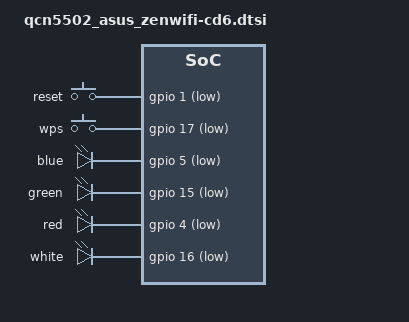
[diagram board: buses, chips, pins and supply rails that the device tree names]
// SPDX-License-Identifier: GPL-2.0-or-later OR MIT

#include "qcn5502_asus.dtsi"

#include <dt-bindings/gpio/gpio.h>
#include <dt-bindings/input/input.h>

/ {
	aliases {
		led-boot = &led_blue;
		led-failsafe = &led_red;
		led-running = &led_blue;
		led-upgrade = &led_red;
	};

	keys {
		compatible = "gpio-keys";

		reset {
			label = "reset";
			linux,code = <KEY_RESTART>;
			gpios = <&gpio 1 GPIO_ACTIVE_LOW>;
			debounce-interval = <60>;
		};

		wps {
			label = "wps";
			linux,code = <KEY_WPS_BUTTON>;
			gpios = <&gpio 17 GPIO_ACTIVE_LOW>;
			debounce-interval = <60>;
		};
	};

	leds {
		compatible = "gpio-leds";

		led_blue: blue {
			label = "blue";
			gpios = <&gpio 5 GPIO_ACTIVE_LOW>;
		};

		green {
			label = "green";
			gpios = <&gpio 15 GPIO_ACTIVE_LOW>;
		};

		led_red: red {
			label = "red";
			gpios = <&gpio 4 GPIO_ACTIVE_LOW>;
		};

		white {
			label = "white";
			gpios = <&gpio 16 GPIO_ACTIVE_LOW>;
		};
	};
};
